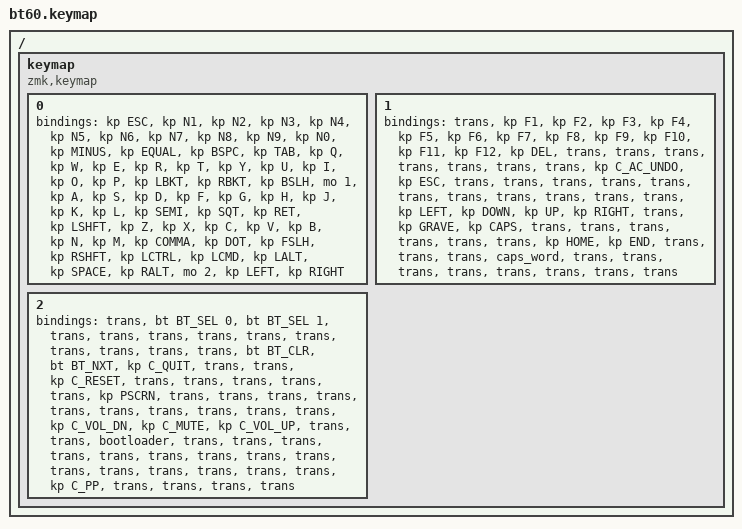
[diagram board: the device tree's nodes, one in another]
# include <behaviors.dtsi>
# include <dt-bindings/zmk/keys.h>
# include <dt-bindings/zmk/bt.h>
/{
	keymap{
		compatible="zmk,keymap";
		0{bindings=<&kp ESC &kp N1 &kp N2 &kp N3 &kp N4 &kp N5 &kp N6 &kp N7 &kp N8 &kp N9 &kp N0 &kp MINUS &kp EQUAL &kp BSPC &kp TAB &kp Q &kp W &kp E &kp R &kp T &kp Y &kp U &kp I &kp O &kp P &kp LBKT &kp RBKT &kp BSLH &mo 1 &kp A &kp S &kp D &kp F &kp G &kp H &kp J &kp K &kp L &kp SEMI &kp SQT &kp RET &kp LSHFT &kp Z &kp X &kp C &kp V &kp B &kp N &kp M &kp COMMA &kp DOT &kp FSLH &kp RSHFT &kp LCTRL &kp LCMD &kp LALT &kp SPACE &kp RALT &mo 2 &kp LEFT &kp RIGHT>;};
		1{bindings=<&trans &kp F1 &kp F2 &kp F3 &kp F4 &kp F5 &kp F6 &kp F7 &kp F8 &kp F9 &kp F10 &kp F11 &kp F12 &kp DEL &trans &trans &trans &trans &trans &trans &trans &kp C_AC_UNDO &kp ESC &trans &trans &trans &trans &trans &trans &trans &trans &trans &trans &trans &kp LEFT &kp DOWN &kp UP &kp RIGHT &trans &kp GRAVE &kp CAPS &trans &trans &trans &trans &trans &trans &kp HOME &kp END &trans &trans &trans &caps_word &trans &trans &trans &trans &trans &trans &trans &trans>;};
		2{bindings=<&trans &bt BT_SEL 0 &bt BT_SEL 1 &trans &trans &trans &trans &trans &trans &trans &trans &trans &trans &bt BT_CLR &bt BT_NXT &kp C_QUIT &trans &trans &kp C_RESET &trans &trans &trans &trans &trans &kp PSCRN &trans &trans &trans &trans &trans &trans &trans &trans &trans &trans &kp C_VOL_DN &kp C_MUTE &kp C_VOL_UP &trans &trans &bootloader &trans &trans &trans &trans &trans &trans &trans &trans &trans &trans &trans &trans &trans &trans &trans &kp C_PP &trans &trans &trans &trans>;};};
};
